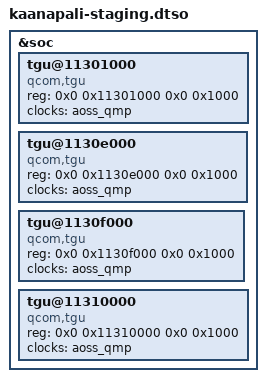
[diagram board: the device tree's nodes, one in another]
// SPDX-License-Identifier: BSD-3-Clause
/*
 * Copyright (c) Qualcomm Technologies, Inc. and/or its subsidiaries.
 *
 * Kaanapali staging overlay - add staging-specific device tree modifications here.
 */

/dts-v1/;
/plugin/;

&soc {
	tgu@11301000 {
		compatible = "qcom,tgu", "arm,primecell";
		reg = <0x0 0x11301000 0x0 0x1000>;

		clocks = <&aoss_qmp>;
		clock-names = "apb_pclk";
	};

	tgu@1130e000 {
		compatible = "qcom,tgu", "arm,primecell";
		reg = <0x0 0x1130e000 0x0 0x1000>;

		clocks = <&aoss_qmp>;
		clock-names = "apb_pclk";
	};

	tgu@1130f000 {
		compatible = "qcom,tgu", "arm,primecell";
		reg = <0x0 0x1130f000 0x0 0x1000>;

		clocks = <&aoss_qmp>;
		clock-names = "apb_pclk";
	};

	tgu@11310000 {
		compatible = "qcom,tgu", "arm,primecell";
		reg = <0x0 0x11310000 0x0 0x1000>;

		clocks = <&aoss_qmp>;
		clock-names = "apb_pclk";
	};
};
